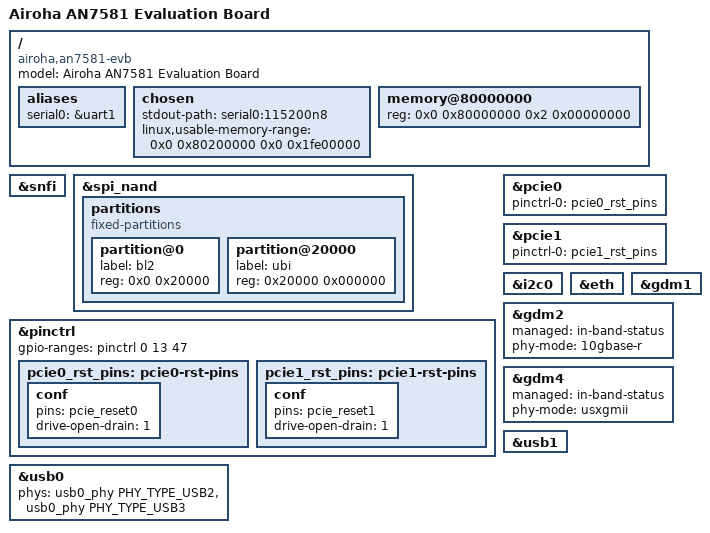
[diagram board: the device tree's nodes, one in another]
// SPDX-License-Identifier: (GPL-2.0-only OR BSD-2-Clause)
/dts-v1/;

#include "an7581.dtsi"

/ {
	model = "Airoha AN7581 Evaluation Board";
	compatible = "airoha,an7581-evb",
		     "airoha,an7581",
		     "airoha,en7581";

	aliases {
		serial0 = &uart1;
	};

	chosen {
		stdout-path = "serial0:115200n8";
		linux,usable-memory-range = <0x0 0x80200000 0x0 0x1fe00000>;
	};

	memory@80000000 {
		device_type = "memory";
		reg = <0x0 0x80000000 0x2 0x00000000>;
	};
};

&snfi {
	status = "okay";
};

&spi_nand {
	partitions {
		compatible = "fixed-partitions";
		#address-cells = <1>;
		#size-cells = <1>;

		partition@0 {
			label = "bl2";
			reg = <0x0 0x20000>;
		};

		partition@20000 {
			label = "ubi";
			reg = <0x20000 0x000000>;
		};
	};
};

&pinctrl {
	gpio-ranges = <&pinctrl 0 13 47>;

	pcie0_rst_pins: pcie0-rst-pins {
		conf {
			pins = "pcie_reset0";
			drive-open-drain = <1>;
		};
	};

	pcie1_rst_pins: pcie1-rst-pins {
		conf {
			pins = "pcie_reset1";
			drive-open-drain = <1>;
		};
	};
};

&pcie0 {
	pinctrl-names = "default";
	pinctrl-0 = <&pcie0_rst_pins>;
	status = "okay";
};

&pcie1 {
	pinctrl-names = "default";
	pinctrl-0 = <&pcie1_rst_pins>;
	status = "okay";
};

&i2c0 {
	status = "okay";
};

&eth {
	status = "okay";
};

&gdm1 {
	status = "okay";
};

&gdm2 {
	status = "okay";

	managed = "in-band-status";
	phy-mode = "10gbase-r";
};

&gdm4 {
	status = "okay";

	managed = "in-band-status";
	phy-mode = "usxgmii";
};

/*
 * USB: both controllers use the SoC default PHY list from an7581.dtsi, i.e.
 * a USB 2.0 port plus the USB 3.0 port of their PHY block.
 *
 * Note on the second controller: its serdes (AIROHA_SCU_SERDES_USB2) is the
 * one that can also be routed to PCIe, and bringing its USB3 port up switches
 * that serdes to USB. To keep it USB 2.0 only, replace its 'phys' with
 * <&usb1_phy PHY_TYPE_USB2> and add "mediatek,u3p-dis-msk = <0x1>;".
 */
&usb0 {
	status = "okay";

	phys = <&usb0_phy PHY_TYPE_USB2>, <&usb0_phy PHY_TYPE_USB3>;
};

&usb1 {
	status = "okay";
};
